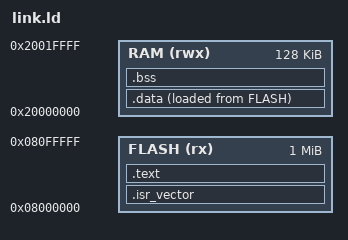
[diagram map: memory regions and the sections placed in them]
/* hwsim-1 Renode twin — STM32F407-class layout. */
MEMORY
{
  FLASH (rx)  : ORIGIN = 0x08000000, LENGTH = 1024K
  RAM   (rwx) : ORIGIN = 0x20000000, LENGTH = 128K
}

_estack = ORIGIN(RAM) + LENGTH(RAM);

SECTIONS
{
  .isr_vector : { KEEP(*(.isr_vector)) } > FLASH
  .text : { *(.text*) *(.rodata*) } > FLASH

  _sidata = LOADADDR(.data);
  .data : {
    _sdata = .;
    *(.data*)
    _edata = .;
  } > RAM AT > FLASH

  .bss (NOLOAD) : {
    _sbss = .;
    *(.bss*) *(COMMON)
    _ebss = .;
  } > RAM
}
